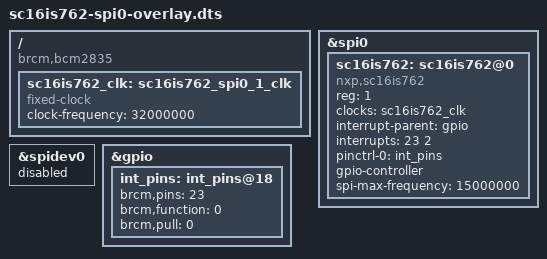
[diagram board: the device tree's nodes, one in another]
/dts-v1/;
/plugin/;

/ {
	compatible = "brcm,bcm2835";

        fragment@0 {
                target = <&spi0>;
                __overlay__ {
                        #address-cells = <1>;
                        #size-cells = <0>;
                        status = "okay";

                        sc16is762: sc16is762@0 {
                                compatible = "nxp,sc16is762";
                                reg = <1>; /* CE1 */
                                clocks = <&sc16is762_clk>;
                                interrupt-parent = <&gpio>;
                                interrupts = <23 2>; /* IRQ_TYPE_EDGE_FALLING */
                                pinctrl-0 = <&int_pins>;
                                pinctrl-names = "default";
                                gpio-controller;
                                #gpio-cells = <2>;
                                spi-max-frequency = <15000000>;
                        };
                };
        };

        fragment@1 {
                target = <&spidev0>;
                __overlay__ {
                        status = "disabled";
                };
        };

        fragment@2 {
                target-path = "/";
                __overlay__ {
                        sc16is762_clk: sc16is762_spi0_1_clk {
                                compatible = "fixed-clock";
                                #clock-cells = <0>;
                                clock-frequency = <32000000>;
                        };
                };
        };

        fragment@3 {
                target = <&gpio>;
                __overlay__ {
                        int_pins: int_pins@18 {
                                        brcm,pins = <23>;
                                        brcm,function = <0>; /* in */
                                        brcm,pull = <0>; /* none */
                        };
                };
        };

        __overrides__ {
                int_pin = <&sc16is762>,"interrupts:0", <&int_pins>,"brcm,pins:0",
                          <&int_pins>,"reg:0";
                xtal = <&sc16is762_clk>,"clock-frequency:0";
        };
};
